AUTOSAR XML (schema 00046)
package /ComponentTypes
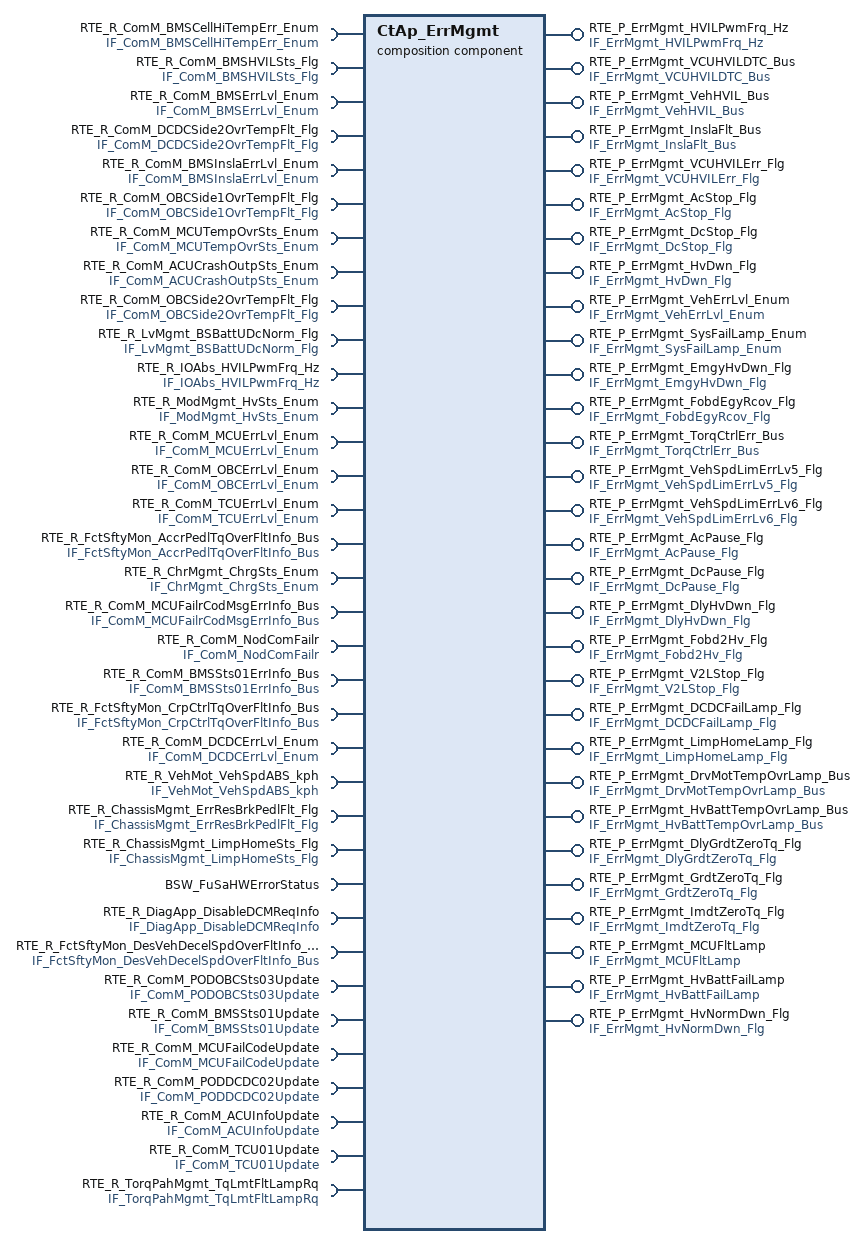
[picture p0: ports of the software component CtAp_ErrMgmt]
  composition sw component type CtAp_ErrMgmt
    12 x require port:
      RTE_R_ComM_BMSCellHiTempErr_Enum: nonqueued-receiver-com-spec{data-element=tec_ComM_BMSCellHiTempErr_Enum, filter=data-filter-type=ALWAYS, init-value=0}, required-interface=IF_ComM_BMSCellHiTempErr_Enum
      RTE_R_ComM_BMSHVILSts_Flg: nonqueued-receiver-com-spec{data-element=tec_ComM_BMSHVILSts_Flg, filter=data-filter-type=ALWAYS, init-value=0}, required-interface=IF_ComM_BMSHVILSts_Flg
      RTE_R_ComM_BMSErrLvl_Enum: nonqueued-receiver-com-spec{data-element=tec_ComM_BMSErrLvl_Enum, filter=data-filter-type=ALWAYS, init-value=0}, required-interface=IF_ComM_BMSErrLvl_Enum
      RTE_R_ComM_DCDCSide2OvrTempFlt_Flg: nonqueued-receiver-com-spec{data-element=tec_ComM_DCDCSide2OvrTempFlt_Flg, filter=data-filter-type=ALWAYS, init-value=0}, required-interface=IF_ComM_DCDCSide2OvrTempFlt_Flg
      RTE_R_ComM_BMSInslaErrLvl_Enum: nonqueued-receiver-com-spec{data-element=tec_ComM_BMSInslaErrLvl_Enum, filter=data-filter-type=ALWAYS, init-value=0}, required-interface=IF_ComM_BMSInslaErrLvl_Enum
      RTE_R_ComM_OBCSide1OvrTempFlt_Flg: nonqueued-receiver-com-spec{data-element=tec_ComM_OBCSide1OvrTempFlt_Flg, filter=data-filter-type=ALWAYS, init-value=0}, required-interface=IF_ComM_OBCSide1OvrTempFlt_Flg
      RTE_R_ComM_MCUTempOvrSts_Enum: nonqueued-receiver-com-spec{data-element=tec_ComM_MCUTempOvrSts_Enum, filter=data-filter-type=ALWAYS, init-value=0}, required-interface=IF_ComM_MCUTempOvrSts_Enum
      RTE_R_ComM_ACUCrashOutpSts_Enum: nonqueued-receiver-com-spec{data-element=tec_ComM_ACUCrashOutpSts_Enum, filter=data-filter-type=ALWAYS, init-value=0}, required-interface=IF_ComM_ACUCrashOutpSts_Enum
      RTE_R_ComM_OBCSide2OvrTempFlt_Flg: nonqueued-receiver-com-spec{data-element=tec_ComM_OBCSide2OvrTempFlt_Flg, filter=data-filter-type=ALWAYS, init-value=0}, required-interface=IF_ComM_OBCSide2OvrTempFlt_Flg
      RTE_R_LvMgmt_BSBattUDcNorm_Flg: nonqueued-receiver-com-spec{data-element=tec_LvMgmt_BSBattUDcNorm_Flg, filter=data-filter-type=ALWAYS, init-value=0}, required-interface=IF_LvMgmt_BSBattUDcNorm_Flg
      RTE_R_IOAbs_HVILPwmFrq_Hz: nonqueued-receiver-com-spec{data-element=tec_IOAbs_HVILPwmFrq_Hz, filter=data-filter-type=ALWAYS, init-value=0}, required-interface=IF_IOAbs_HVILPwmFrq_Hz
      RTE_R_ModMgmt_HvSts_Enum: nonqueued-receiver-com-spec{data-element=tec_ModMgmt_HvSts_Enum, filter=data-filter-type=ALWAYS, init-value=0}, required-interface=IF_ModMgmt_HvSts_Enum
    5 x provide port:
      RTE_P_ErrMgmt_HVILPwmFrq_Hz: nonqueued-sender-com-spec{data-element=tec_ErrMgmt_HVILPwmFrq_Hz, init-value=0}, provided-interface=IF_ErrMgmt_HVILPwmFrq_Hz
      RTE_P_ErrMgmt_VCUHVILDTC_Bus: nonqueued-sender-com-spec{data-element=tec_ErrMgmt_VCUHVILDTC_Bus, init-value=fields=[ErrMgmt_MonStatVCUHVIL:0, ErrMgmt_MonResVCUHVIL:0, ErrMgmt_ErrStatVCUHVIL:0, ErrMgmt_ErrResVCUHVIL:0]}, provided-interface=IF_ErrMgmt_VCUHVILDTC_Bus
      RTE_P_ErrMgmt_VehHVIL_Bus: nonqueued-sender-com-spec{data-element=tec_ErrMgmt_VehHVIL_Bus, init-value=fields=[ErrMgmt_MonStatVehHVIL:0, ErrMgmt_MonResVehHVIL:0, ErrMgmt_ErrStatVehHVIL:0, ErrMgmt_ErrResVehHVIL:0]}, provided-interface=IF_ErrMgmt_VehHVIL_Bus
      RTE_P_ErrMgmt_InslaFlt_Bus: nonqueued-sender-com-spec{data-element=tec_ErrMgmt_InslaFlt_Bus, init-value=fields=[ErrMgmt_MonStatVehHVInsla:0, ErrMgmt_MonResVehHVInsla:0, ErrMgmt_ErrStatVehHVInsla:0, ErrMgmt_ErrResVehHVInsla:0]}, provided-interface=IF_ErrMgmt_InslaFlt_Bus
      RTE_P_ErrMgmt_VCUHVILErr_Flg: nonqueued-sender-com-spec{data-element=tec_ErrMgmt_VCUHVILErr_Flg, init-value=0}, provided-interface=IF_ErrMgmt_VCUHVILErr_Flg
    10 x require port:
      RTE_R_ComM_MCUErrLvl_Enum: nonqueued-receiver-com-spec{data-element=tec_ComM_MCUErrLvl_Enum, filter=data-filter-type=ALWAYS, init-value=0}, required-interface=IF_ComM_MCUErrLvl_Enum
      RTE_R_ComM_OBCErrLvl_Enum: nonqueued-receiver-com-spec{data-element=tec_ComM_OBCErrLvl_Enum, filter=data-filter-type=ALWAYS, init-value=0}, required-interface=IF_ComM_OBCErrLvl_Enum
      RTE_R_ComM_TCUErrLvl_Enum: nonqueued-receiver-com-spec{data-element=tec_ComM_TCUErrLvl_Enum, filter=data-filter-type=ALWAYS, init-value=0}, required-interface=IF_ComM_TCUErrLvl_Enum
      RTE_R_FctSftyMon_AccrPedlTqOverFltInfo_Bus: nonqueued-receiver-com-spec{data-element=tec_FctSftyMon_AccrPedlTqOverFltInfo_Bus, filter=data-filter-type=ALWAYS, init-value=fields=[FctSftyMon_MonStatAccrPedlTqOverFltInfo:0, FctSftyMon_MonResAccrPedlTqOverFltInfo:0, FctSftyMon_ErrStatAccrPedlTqOverFltInfo:0, FctSftyMon_ErrResAccrPedlTqOverFltInfo:0]}, required-interface=IF_FctSftyMon_AccrPedlTqOverFltInfo_Bus
      RTE_R_ChrMgmt_ChrgSts_Enum: nonqueued-receiver-com-spec{data-element=tec_ChrMgmt_ChrgSts_Enum, filter=data-filter-type=ALWAYS, init-value=0}, required-interface=IF_ChrMgmt_ChrgSts_Enum
      RTE_R_ComM_MCUFailrCodMsgErrInfo_Bus: required-interface=IF_ComM_MCUFailrCodMsgErrInfo_Bus
        required-com-specs:
          data-element=tec_ComM_MCUFailrCodCRCInfo_Bus, filter=data-filter-type=ALWAYS, init-value=fields=[ComM_MonStatMCUFailrCodCRCErrorInfo:0, ComM_MonResMCUFailrCodCRCErrorInfo:0, ComM_ErrStatMCUFailrCodCRCErrorInfo:0, ComM_ErrResMCUFailrCodCRCErrorInfo:0]
          data-element=tec_ComM_MCUFailrCodE2ETimeoutInfo_Bus, filter=data-filter-type=ALWAYS, init-value=fields=[ComM_MonStatMCUFailrCodE2ETimeouInfo:0, ComM_MonResMCUFailrCodE2ETimeoutInfo:0, ComM_ErrStatMCUFailrCodE2ETimeoutInfo:0, ComM_ErrResMCUFailrCodE2ETimeoutInfo:0]
          data-element=tec_ComM_MCUFailrCodCRCDTCInfo_Bus, filter=data-filter-type=ALWAYS, init-value=fields=[ComM_MonStatMCUFailrCodCRCDTCErrorInfo:0, ComM_MonResMCUFailrCodCRCDTCErrorInfo:0, ComM_ErrStatMCUFailrCodCRCDTCErrorInfo:0, ComM_ErrResMCUFailrCodCRCDTCErrorInfo:0]
          data-element=tec_ComM_MCUFailrCodTimeoutDTCInfo_Bus, filter=data-filter-type=ALWAYS, init-value=fields=[ComM_MonStatMCUFailrCodTimeoutDTCErrorInfo:0, ComM_MonResMCUFailrCodTimeoutDTCErrorInfo:0, ComM_ErrStatMCUFailrCodTimeoutDTCErrorInfo:0, ComM_ErrResMCUFailrCodTimeoutDTCErrorInfo:0]
      RTE_R_ComM_NodComFailr: required-interface=IF_ComM_NodComFailr
        required-com-specs:
          data-element=tec_ComM_SGWNodComFailr_Flg, filter=data-filter-type=ALWAYS, init-value=0
          data-element=tec_ComM_CGWNodComFailr_Flg, filter=data-filter-type=ALWAYS, init-value=0
          data-element=tec_ComM_TCUNodComFailr_Flg, filter=data-filter-type=ALWAYS, init-value=0
          data-element=tec_ComM_BCMNodComFailr_Flg, filter=data-filter-type=ALWAYS, init-value=0
          data-element=tec_ComM_PRNDNodComFailr_Flg, filter=data-filter-type=ALWAYS, init-value=0
          data-element=tec_ComM_IVINodComFailr_Flg, filter=data-filter-type=ALWAYS, init-value=0
          data-element=tec_ComM_DCDCNodComFailr_Flg, filter=data-filter-type=ALWAYS, init-value=0
          data-element=tec_ComM_OBCNodComFailr_Flg, filter=data-filter-type=ALWAYS, init-value=0
          data-element=tec_ComM_CHIBSNodComFailr_Flg, filter=data-filter-type=ALWAYS, init-value=0
          data-element=tec_ComM_MCUNodComFailr_Flg, filter=data-filter-type=ALWAYS, init-value=0
          data-element=tec_ComM_EVCOMNodComFailr_Flg, filter=data-filter-type=ALWAYS, init-value=0
          data-element=tec_ComM_EPTIBSNodComFailr_Flg, filter=data-filter-type=ALWAYS, init-value=0
          data-element=tec_ComM_DCMNodComFailr_Flg, filter=data-filter-type=ALWAYS, init-value=0
          data-element=tec_ComM_BMSNodComFailr_Flg, filter=data-filter-type=ALWAYS, init-value=0
          data-element=tec_ComM_ACUNodComFailr_Flg, filter=data-filter-type=ALWAYS, init-value=0
          data-element=tec_ComM_APTCNodComFailr_Flg, filter=data-filter-type=ALWAYS, init-value=0
          data-element=tec_ComM_ADCUNodComFailr_Flg, filter=data-filter-type=ALWAYS, init-value=0
          data-element=tec_ComM_DCMRRNodComFailr_Flg, filter=data-filter-type=ALWAYS, init-value=0
          data-element=tec_ComM_DCMRLNodComFailr_Flg, filter=data-filter-type=ALWAYS, init-value=0
          data-element=tec_ComM_DCMFRNodComFailr_Flg, filter=data-filter-type=ALWAYS, init-value=0
          data-element=tec_ComM_DCMFLNodComFailr_Flg, filter=data-filter-type=ALWAYS, init-value=0
          data-element=tec_ComM_SGWCHNodComFailr_Flg, filter=data-filter-type=ALWAYS, init-value=0
      RTE_R_ComM_BMSSts01ErrInfo_Bus: required-interface=IF_ComM_BMSSts01ErrInfo_Bus
        required-com-specs:
          data-element=tec_ComM_BMSSts01TimeoutInfo_Bus, filter=data-filter-type=ALWAYS, init-value=fields=[ComM_MonStatBMSSts01TimeoutInfo:0, ComM_MonResBMSSts01TimeoutInfo:0, ComM_ErrStatBMSSts01TimeoutInfo:0, ComM_ErrResBMSSts01TimeoutInfo:0]
          data-element=tec_ComM_BMSSts01CRCDTCInfo_Bus, filter=data-filter-type=ALWAYS, init-value=fields=[ComM_MonStatBMSSts01CRCDTCErrorInfo:0, ComM_MonResBMSSts01CRCDTCErrorInfo:0, ComM_ErrStatBMSSts01CRCDTCErrorInfo:0, ComM_ErrResBMSSts01CRCDTCErrorInfo:0]
          data-element=tec_ComM_BMSSts01CRCInfo_Bus, filter=data-filter-type=ALWAYS, init-value=fields=[ComM_MonStatBMSSts01CRCErrorInfo:0, ComM_MonResBMSSts01CRCErrorInfo:0, ComM_ErrStatBMSSts01CRCErrorInfo:0, ComM_ErrResBMSSts01CRCErrorInfo:0]
          data-element=tec_ComM_BMSSts01TimeoutDTCInfo_Bus, filter=data-filter-type=ALWAYS, init-value=fields=[ComM_MonStatBMSSts01TimeoutDTCErrorInfo:0, ComM_MonResBMSSts01TimeoutDTCErrorInfo:0, ComM_ErrStatBMSSts01TimeoutDTCErrorInfo:0, ComM_ErrResBMSSts01TimeoutDTCErrorInfo:0]
          data-element=tec_ComM_BMSSts01E2ETimeoutInfo_Bus, filter=data-filter-type=ALWAYS, init-value=fields=[ComM_MonStatBMSSts01E2ETimeoutInfo:0, ComM_MonResBMSSts01E2ETimeoutInfo:0, ComM_ErrStatBMSSts01E2ETimeoutInfo:0, ComM_ErrResBMSSts01E2ETimeoutInfo:0]
      RTE_R_FctSftyMon_CrpCtrlTqOverFltInfo_Bus: nonqueued-receiver-com-spec{data-element=tec_FctSftyMon_CrpCtrlTqOverFltInfo_Bus, filter=data-filter-type=ALWAYS, init-value=fields=[FctSftyMon_MonStatCrpCtrlTqOverFltInfo:0, FctSftyMon_MonResCrpCtrlTqOverFltInfo:0, FctSftyMon_ErrStatCrpCtrlTqOverFltInfo:0, FctSftyMon_ErrResCrpCtrlTqOverFltInfo:0]}, required-interface=IF_FctSftyMon_CrpCtrlTqOverFltInfo_Bus
      RTE_R_ComM_DCDCErrLvl_Enum: nonqueued-receiver-com-spec{data-element=tec_ComM_DCDCErrLvl_Enum, filter=data-filter-type=ALWAYS, init-value=0}, required-interface=IF_ComM_DCDCErrLvl_Enum
    17 x provide port:
      RTE_P_ErrMgmt_AcStop_Flg: nonqueued-sender-com-spec{data-element=tec_ErrMgmt_AcStop_Flg, init-value=0}, provided-interface=IF_ErrMgmt_AcStop_Flg
      RTE_P_ErrMgmt_DcStop_Flg: nonqueued-sender-com-spec{data-element=tec_ErrMgmt_DcStop_Flg, init-value=0}, provided-interface=IF_ErrMgmt_DcStop_Flg
      RTE_P_ErrMgmt_HvDwn_Flg: nonqueued-sender-com-spec{data-element=tec_ErrMgmt_HvDwn_Flg, init-value=0}, provided-interface=IF_ErrMgmt_HvDwn_Flg
      RTE_P_ErrMgmt_VehErrLvl_Enum: nonqueued-sender-com-spec{data-element=tec_ErrMgmt_VehErrLvl_Enum, init-value=0}, provided-interface=IF_ErrMgmt_VehErrLvl_Enum
      RTE_P_ErrMgmt_SysFailLamp_Enum: nonqueued-sender-com-spec{data-element=tec_ErrMgmt_SysFailLamp_Enum, init-value=0}, provided-interface=IF_ErrMgmt_SysFailLamp_Enum
      RTE_P_ErrMgmt_EmgyHvDwn_Flg: nonqueued-sender-com-spec{data-element=tec_ErrMgmt_EmgyHvDwn_Flg, init-value=0}, provided-interface=IF_ErrMgmt_EmgyHvDwn_Flg
      RTE_P_ErrMgmt_FobdEgyRcov_Flg: nonqueued-sender-com-spec{data-element=tec_ErrMgmt_FobdEgyRcov_Flg, init-value=0}, provided-interface=IF_ErrMgmt_FobdEgyRcov_Flg
      RTE_P_ErrMgmt_TorqCtrlErr_Bus: nonqueued-sender-com-spec{data-element=tec_ErrMgmt_TorqCtrlErr_Bus, init-value=fields=[ErrMgmt_DlyGrdtZeroTq_Flg:0, ErrMgmt_GrdtZeroTq_Flg:0, ErrMgmt_ImdtZeroTq_Flg:0, ErrMgmt_VehSpdLim_kph:0, ErrMgmt_VehSpdLimEna_Flg:0]}, provided-interface=IF_ErrMgmt_TorqCtrlErr_Bus
      RTE_P_ErrMgmt_VehSpdLimErrLv5_Flg: nonqueued-sender-com-spec{data-element=tec_ErrMgmt_VehSpdLimErrLv5_Flg, init-value=0}, provided-interface=IF_ErrMgmt_VehSpdLimErrLv5_Flg
      RTE_P_ErrMgmt_VehSpdLimErrLv6_Flg: nonqueued-sender-com-spec{data-element=tec_ErrMgmt_VehSpdLimErrLv6_Flg, init-value=0}, provided-interface=IF_ErrMgmt_VehSpdLimErrLv6_Flg
      RTE_P_ErrMgmt_AcPause_Flg: nonqueued-sender-com-spec{data-element=tec_ErrMgmt_AcPause_Flg, init-value=0}, provided-interface=IF_ErrMgmt_AcPause_Flg
      RTE_P_ErrMgmt_DcPause_Flg: nonqueued-sender-com-spec{data-element=tec_ErrMgmt_DcPause_Flg, init-value=0}, provided-interface=IF_ErrMgmt_DcPause_Flg
      RTE_P_ErrMgmt_DlyHvDwn_Flg: nonqueued-sender-com-spec{data-element=tec_ErrMgmt_DlyHvDwn_Flg, init-value=0}, provided-interface=IF_ErrMgmt_DlyHvDwn_Flg
      RTE_P_ErrMgmt_Fobd2Hv_Flg: nonqueued-sender-com-spec{data-element=tec_ErrMgmt_Fobd2Hv_Flg, init-value=0}, provided-interface=IF_ErrMgmt_Fobd2Hv_Flg
      RTE_P_ErrMgmt_V2LStop_Flg: nonqueued-sender-com-spec{data-element=tec_ErrMgmt_V2LStop_Flg, init-value=0}, provided-interface=IF_ErrMgmt_V2LStop_Flg
      RTE_P_ErrMgmt_DCDCFailLamp_Flg: nonqueued-sender-com-spec{data-element=tec_ErrMgmt_DCDCFailLamp_Flg, init-value=0}, provided-interface=IF_ErrMgmt_DCDCFailLamp_Flg
      RTE_P_ErrMgmt_LimpHomeLamp_Flg: nonqueued-sender-com-spec{data-element=tec_ErrMgmt_LimpHomeLamp_Flg, init-value=0}, provided-interface=IF_ErrMgmt_LimpHomeLamp_Flg
    require port RTE_R_VehMot_VehSpdABS_kph: nonqueued-receiver-com-spec{data-element=tec_VehMot_VehSpdABS_kph, filter=data-filter-type=ALWAYS, init-value=0}, required-interface=IF_VehMot_VehSpdABS_kph
    require port RTE_R_ChassisMgmt_ErrResBrkPedlFlt_Flg: nonqueued-receiver-com-spec{data-element=tec_ChassisMgmt_ErrResBrkPedlFlt_Flg, filter=data-filter-type=ALWAYS, init-value=0}, required-interface=IF_ChassisMgmt_ErrResBrkPedlFlt_Flg
    require port RTE_R_ChassisMgmt_LimpHomeSts_Flg: nonqueued-receiver-com-spec{data-element=tec_ChassisMgmt_LimpHomeSts_Flg, filter=data-filter-type=ALWAYS, init-value=0}, required-interface=IF_ChassisMgmt_LimpHomeSts_Flg
    5 x provide port:
      RTE_P_ErrMgmt_DrvMotTempOvrLamp_Bus: nonqueued-sender-com-spec{data-element=tec_ErrMgmt_DrvMotTempOvrLamp_Bus, init-value=fields=[ErrMgmt_MonStatMCUTempOvr:0, ErrMgmt_MonResMCUTempOvr:0, ErrMgmt_ErrStatMCUTempOvr:0, ErrMgmt_ErrResMCUTempOvr:0]}, provided-interface=IF_ErrMgmt_DrvMotTempOvrLamp_Bus
      RTE_P_ErrMgmt_HvBattTempOvrLamp_Bus: nonqueued-sender-com-spec{data-element=tec_ErrMgmt_HvBattTempOvrLamp_Bus, init-value=fields=[ErrMgmt_MonStatBMSTempOvr:0, ErrMgmt_MonResBMSTempOvr:0, ErrMgmt_ErrStatBMSTempOvr:0, ErrMgmt_ErrResBMSTempOvr:0]}, provided-interface=IF_ErrMgmt_HvBattTempOvrLamp_Bus
      RTE_P_ErrMgmt_DlyGrdtZeroTq_Flg: nonqueued-sender-com-spec{data-element=tec_ErrMgmt_DlyGrdtZeroTq_Flg, init-value=0}, provided-interface=IF_ErrMgmt_DlyGrdtZeroTq_Flg
      RTE_P_ErrMgmt_GrdtZeroTq_Flg: nonqueued-sender-com-spec{data-element=tec_ErrMgmt_GrdtZeroTq_Flg, init-value=0}, provided-interface=IF_ErrMgmt_GrdtZeroTq_Flg
      RTE_P_ErrMgmt_ImdtZeroTq_Flg: nonqueued-sender-com-spec{data-element=tec_ErrMgmt_ImdtZeroTq_Flg, init-value=0}, provided-interface=IF_ErrMgmt_ImdtZeroTq_Flg
    require port BSW_FuSaHWErrorStatus: nonqueued-receiver-com-spec{data-element=HWErrorStatus, filter=data-filter-type=ALWAYS, init-value=0}, required-interface=BSW_FuSaHWErrorStatus
    provide port RTE_P_ErrMgmt_MCUFltLamp: nonqueued-sender-com-spec{data-element=tec_ErrMgmt_MCUFltLamp, init-value=0}, provided-interface=IF_ErrMgmt_MCUFltLamp
    provide port RTE_P_ErrMgmt_HvBattFailLamp: nonqueued-sender-com-spec{data-element=tec_ErrMgmt_HvBattFailLamp, init-value=0}, provided-interface=IF_ErrMgmt_HvBattFailLamp
    provide port RTE_P_ErrMgmt_HvNormDwn_Flg: nonqueued-sender-com-spec{data-element=tec_ErrMgmt_HvNormDwn_Flg, init-value=0}, provided-interface=IF_ErrMgmt_HvNormDwn_Flg
    9 x require port:
      RTE_R_DiagApp_DisableDCMReqInfo: nonqueued-receiver-com-spec{data-element=tec_DiagApp_DisableDCMReqInfo, filter=data-filter-type=ALWAYS, init-value=0}, required-interface=IF_DiagApp_DisableDCMReqInfo
      RTE_R_FctSftyMon_DesVehDecelSpdOverFltInfo_Bus: nonqueued-receiver-com-spec{data-element=tec_FctSftyMon_DesVehDecelSpdOverFltInfo_Bus, filter=data-filter-type=ALWAYS, init-value=fields=[FctSftyMon_MonStatDesVehDecelSpdOverFltInfo:0, FctSftyMon_MonResDesVehDecelSpdOverFltInfo:0, FctSftyMon_ErrStatDesVehDecelSpdOverFltInfo:0, FctSftyMon_ErrResDesVehDecelSpdOverFltInfo:0]}, required-interface=IF_FctSftyMon_DesVehDecelSpdOverFltInfo_Bus
      RTE_R_ComM_PODOBCSts03Update: nonqueued-receiver-com-spec{data-element=tec_ComM_PODOBCSts03Update, filter=data-filter-type=ALWAYS, init-value=0}, required-interface=IF_ComM_PODOBCSts03Update
      RTE_R_ComM_BMSSts01Update: nonqueued-receiver-com-spec{data-element=tec_ComM_BMSSts01Update, filter=data-filter-type=ALWAYS, init-value=0}, required-interface=IF_ComM_BMSSts01Update
      RTE_R_ComM_MCUFailCodeUpdate: nonqueued-receiver-com-spec{data-element=tec_ComM_MCUFailCodeUpdate, filter=data-filter-type=ALWAYS, init-value=0}, required-interface=IF_ComM_MCUFailCodeUpdate
      RTE_R_ComM_PODDCDC02Update: nonqueued-receiver-com-spec{data-element=tec_ComM_PODDCDC02Update, filter=data-filter-type=ALWAYS, init-value=0}, required-interface=IF_ComM_PODDCDC02Update
      RTE_R_ComM_ACUInfoUpdate: nonqueued-receiver-com-spec{data-element=tec_ComM_ACUInfoUpdate, filter=data-filter-type=ALWAYS, init-value=0}, required-interface=IF_ComM_ACUInfoUpdate
      RTE_R_ComM_TCU01Update: nonqueued-receiver-com-spec{data-element=tec_ComM_TCU01Update, filter=data-filter-type=ALWAYS, init-value=0}, required-interface=IF_ComM_TCU01Update
      RTE_R_TorqPahMgmt_TqLmtFltLampRq: nonqueued-receiver-com-spec{data-element=tec_TorqPahMgmt_TqLmtFltLampRq, filter=data-filter-type=ALWAYS, init-value=0}, required-interface=IF_TorqPahMgmt_TqLmtFltLampRq
    component CtAp_HVSfty: type=CtAp_HVSfty
    component CtAp_FltReactn: type=CtAp_FltReactn
    delegate CtAp_HVSfty.RTE_R_ComM_BMSCellHiTempErr_Enum <-> outer port RTE_R_ComM_BMSCellHiTempErr_Enum
    delegate CtAp_HVSfty.RTE_R_ComM_BMSHVILSts_Flg <-> outer port RTE_R_ComM_BMSHVILSts_Flg
    delegate CtAp_HVSfty.RTE_R_ComM_DCDCSide2OvrTempFlt_Flg <-> outer port RTE_R_ComM_DCDCSide2OvrTempFlt_Flg
    delegate CtAp_HVSfty.RTE_R_ComM_BMSInslaErrLvl_Enum <-> outer port RTE_R_ComM_BMSInslaErrLvl_Enum
    delegate CtAp_HVSfty.RTE_R_ComM_OBCSide1OvrTempFlt_Flg <-> outer port RTE_R_ComM_OBCSide1OvrTempFlt_Flg
    delegate CtAp_HVSfty.RTE_R_ComM_MCUTempOvrSts_Enum <-> outer port RTE_R_ComM_MCUTempOvrSts_Enum
    delegate CtAp_HVSfty.RTE_R_ComM_OBCSide2OvrTempFlt_Flg <-> outer port RTE_R_ComM_OBCSide2OvrTempFlt_Flg
    delegate CtAp_HVSfty.RTE_R_LvMgmt_BSBattUDcNorm_Flg <-> outer port RTE_R_LvMgmt_BSBattUDcNorm_Flg
    delegate CtAp_HVSfty.RTE_R_IOAbs_HVILPwmFrq_Hz <-> outer port RTE_R_IOAbs_HVILPwmFrq_Hz
    delegate CtAp_HVSfty.RTE_P_ErrMgmt_HVILPwmFrq_Hz <-> outer port RTE_P_ErrMgmt_HVILPwmFrq_Hz
    delegate CtAp_HVSfty.RTE_P_ErrMgmt_VCUHVILDTC_Bus <-> outer port RTE_P_ErrMgmt_VCUHVILDTC_Bus
    delegate CtAp_HVSfty.RTE_P_ErrMgmt_VehHVIL_Bus <-> outer port RTE_P_ErrMgmt_VehHVIL_Bus
    delegate CtAp_HVSfty.RTE_P_ErrMgmt_InslaFlt_Bus <-> outer port RTE_P_ErrMgmt_InslaFlt_Bus
    delegate CtAp_HVSfty.RTE_P_ErrMgmt_VCUHVILErr_Flg <-> outer port RTE_P_ErrMgmt_VCUHVILErr_Flg
    delegate CtAp_FltReactn.RTE_R_ComM_ACUCrashOutpSts_Enum <-> outer port RTE_R_ComM_ACUCrashOutpSts_Enum
    delegate CtAp_FltReactn.RTE_R_ComM_MCUErrLvl_Enum <-> outer port RTE_R_ComM_MCUErrLvl_Enum
    delegate CtAp_FltReactn.RTE_R_ComM_OBCErrLvl_Enum <-> outer port RTE_R_ComM_OBCErrLvl_Enum
    delegate CtAp_FltReactn.RTE_R_ComM_TCUErrLvl_Enum <-> outer port RTE_R_ComM_TCUErrLvl_Enum
    delegate CtAp_FltReactn.RTE_R_FctSftyMon_AccrPedlTqOverFltInfo_Bus <-> outer port RTE_R_FctSftyMon_AccrPedlTqOverFltInfo_Bus
    delegate CtAp_FltReactn.RTE_R_ChrMgmt_ChrgSts_Enum <-> outer port RTE_R_ChrMgmt_ChrgSts_Enum
    delegate CtAp_FltReactn.RTE_R_ComM_MCUFailrCodMsgErrInfo_Bus <-> outer port RTE_R_ComM_MCUFailrCodMsgErrInfo_Bus
    delegate CtAp_FltReactn.RTE_R_ComM_NodComFailr <-> outer port RTE_R_ComM_NodComFailr
    delegate CtAp_FltReactn.RTE_R_ModMgmt_HvSts_Enum <-> outer port RTE_R_ModMgmt_HvSts_Enum
    delegate CtAp_FltReactn.RTE_R_ComM_BMSSts01ErrInfo_Bus <-> outer port RTE_R_ComM_BMSSts01ErrInfo_Bus
    delegate CtAp_FltReactn.RTE_R_FctSftyMon_CrpCtrlTqOverFltInfo_Bus <-> outer port RTE_R_FctSftyMon_CrpCtrlTqOverFltInfo_Bus
    delegate CtAp_FltReactn.RTE_R_ComM_BMSErrLvl_Enum <-> outer port RTE_R_ComM_BMSErrLvl_Enum
    delegate CtAp_FltReactn.RTE_R_ComM_DCDCErrLvl_Enum <-> outer port RTE_R_ComM_DCDCErrLvl_Enum
    delegate CtAp_FltReactn.RTE_R_ComM_BMSInslaErrLvl_Enum <-> outer port RTE_R_ComM_BMSInslaErrLvl_Enum
    delegate CtAp_FltReactn.RTE_P_ErrMgmt_AcStop_Flg <-> outer port RTE_P_ErrMgmt_AcStop_Flg
    delegate CtAp_FltReactn.RTE_P_ErrMgmt_DcStop_Flg <-> outer port RTE_P_ErrMgmt_DcStop_Flg
    delegate CtAp_FltReactn.RTE_P_ErrMgmt_HvDwn_Flg <-> outer port RTE_P_ErrMgmt_HvDwn_Flg
    delegate CtAp_FltReactn.RTE_P_ErrMgmt_VehErrLvl_Enum <-> outer port RTE_P_ErrMgmt_VehErrLvl_Enum
    delegate CtAp_FltReactn.RTE_P_ErrMgmt_SysFailLamp_Enum <-> outer port RTE_P_ErrMgmt_SysFailLamp_Enum
    delegate CtAp_FltReactn.RTE_P_ErrMgmt_EmgyHvDwn_Flg <-> outer port RTE_P_ErrMgmt_EmgyHvDwn_Flg
    delegate CtAp_FltReactn.RTE_P_ErrMgmt_FobdEgyRcov_Flg <-> outer port RTE_P_ErrMgmt_FobdEgyRcov_Flg
    delegate CtAp_FltReactn.RTE_P_ErrMgmt_TorqCtrlErr_Bus <-> outer port RTE_P_ErrMgmt_TorqCtrlErr_Bus
    delegate CtAp_FltReactn.RTE_P_ErrMgmt_VehSpdLimErrLv5_Flg <-> outer port RTE_P_ErrMgmt_VehSpdLimErrLv5_Flg
    delegate CtAp_FltReactn.RTE_P_ErrMgmt_VehSpdLimErrLv6_Flg <-> outer port RTE_P_ErrMgmt_VehSpdLimErrLv6_Flg
    delegate CtAp_FltReactn.RTE_P_ErrMgmt_AcPause_Flg <-> outer port RTE_P_ErrMgmt_AcPause_Flg
    delegate CtAp_FltReactn.RTE_P_ErrMgmt_DcPause_Flg <-> outer port RTE_P_ErrMgmt_DcPause_Flg
    delegate CtAp_FltReactn.RTE_P_ErrMgmt_DlyHvDwn_Flg <-> outer port RTE_P_ErrMgmt_DlyHvDwn_Flg
    delegate CtAp_FltReactn.RTE_P_ErrMgmt_Fobd2Hv_Flg <-> outer port RTE_P_ErrMgmt_Fobd2Hv_Flg
    delegate CtAp_FltReactn.RTE_P_ErrMgmt_V2LStop_Flg <-> outer port RTE_P_ErrMgmt_V2LStop_Flg
    delegate CtAp_FltReactn.RTE_P_ErrMgmt_DCDCFailLamp_Flg <-> outer port RTE_P_ErrMgmt_DCDCFailLamp_Flg
    delegate CtAp_FltReactn.RTE_P_ErrMgmt_LimpHomeLamp_Flg <-> outer port RTE_P_ErrMgmt_LimpHomeLamp_Flg
    delegate CtAp_HVSfty.RTE_R_ComM_NodComFailr <-> outer port RTE_R_ComM_NodComFailr
    connect CtAp_HVSfty.RTE_P_ErrMgmt_VehHVIL_Bus -> CtAp_FltReactn.RTE_R_ErrMgmt_VehHVIL_Bus
    delegate CtAp_FltReactn.RTE_R_VehMot_VehSpdABS_kph <-> outer port RTE_R_VehMot_VehSpdABS_kph
    delegate CtAp_FltReactn.RTE_R_ChassisMgmt_ErrResBrkPedlFlt_Flg <-> outer port RTE_R_ChassisMgmt_ErrResBrkPedlFlt_Flg
    delegate CtAp_FltReactn.RTE_R_ChassisMgmt_LimpHomeSts_Flg <-> outer port RTE_R_ChassisMgmt_LimpHomeSts_Flg
    delegate CtAp_HVSfty.RTE_P_ErrMgmt_DrvMotTempOvrLamp_Bus <-> outer port RTE_P_ErrMgmt_DrvMotTempOvrLamp_Bus
    delegate CtAp_HVSfty.RTE_P_ErrMgmt_HvBattTempOvrLamp_Bus <-> outer port RTE_P_ErrMgmt_HvBattTempOvrLamp_Bus
    delegate CtAp_FltReactn.RTE_P_ErrMgmt_DlyGrdtZeroTq_Flg <-> outer port RTE_P_ErrMgmt_DlyGrdtZeroTq_Flg
    delegate CtAp_FltReactn.RTE_P_ErrMgmt_GrdtZeroTq_Flg <-> outer port RTE_P_ErrMgmt_GrdtZeroTq_Flg
    delegate CtAp_FltReactn.RTE_P_ErrMgmt_ImdtZeroTq_Flg <-> outer port RTE_P_ErrMgmt_ImdtZeroTq_Flg
    delegate CtAp_FltReactn.BSW_FuSaHWErrorStatus <-> outer port BSW_FuSaHWErrorStatus
    delegate CtAp_FltReactn.RTE_P_ErrMgmt_MCUFltLamp <-> outer port RTE_P_ErrMgmt_MCUFltLamp
    delegate CtAp_FltReactn.RTE_P_ErrMgmt_HvBattFailLamp <-> outer port RTE_P_ErrMgmt_HvBattFailLamp
    delegate CtAp_FltReactn.RTE_P_ErrMgmt_HvNormDwn_Flg <-> outer port RTE_P_ErrMgmt_HvNormDwn_Flg
    delegate CtAp_HVSfty.RTE_R_DiagApp_DisableDCMReqInfo <-> outer port RTE_R_DiagApp_DisableDCMReqInfo
    delegate CtAp_FltReactn.RTE_R_FctSftyMon_DesVehDecelSpdOverFltInfo_Bus <-> outer port RTE_R_FctSftyMon_DesVehDecelSpdOverFltInfo_Bus
    delegate CtAp_FltReactn.RTE_R_ComM_PODOBCSts03Update <-> outer port RTE_R_ComM_PODOBCSts03Update
    delegate CtAp_FltReactn.RTE_R_ComM_BMSSts01Update <-> outer port RTE_R_ComM_BMSSts01Update
    delegate CtAp_FltReactn.RTE_R_ComM_MCUFailCodeUpdate <-> outer port RTE_R_ComM_MCUFailCodeUpdate
    delegate CtAp_FltReactn.RTE_R_ComM_PODDCDC02Update <-> outer port RTE_R_ComM_PODDCDC02Update
    delegate CtAp_FltReactn.RTE_R_ComM_ACUInfoUpdate <-> outer port RTE_R_ComM_ACUInfoUpdate
    delegate CtAp_FltReactn.RTE_R_ComM_TCU01Update <-> outer port RTE_R_ComM_TCU01Update
    delegate CtAp_FltReactn.RTE_R_TorqPahMgmt_TqLmtFltLampRq <-> outer port RTE_R_TorqPahMgmt_TqLmtFltLampRq
